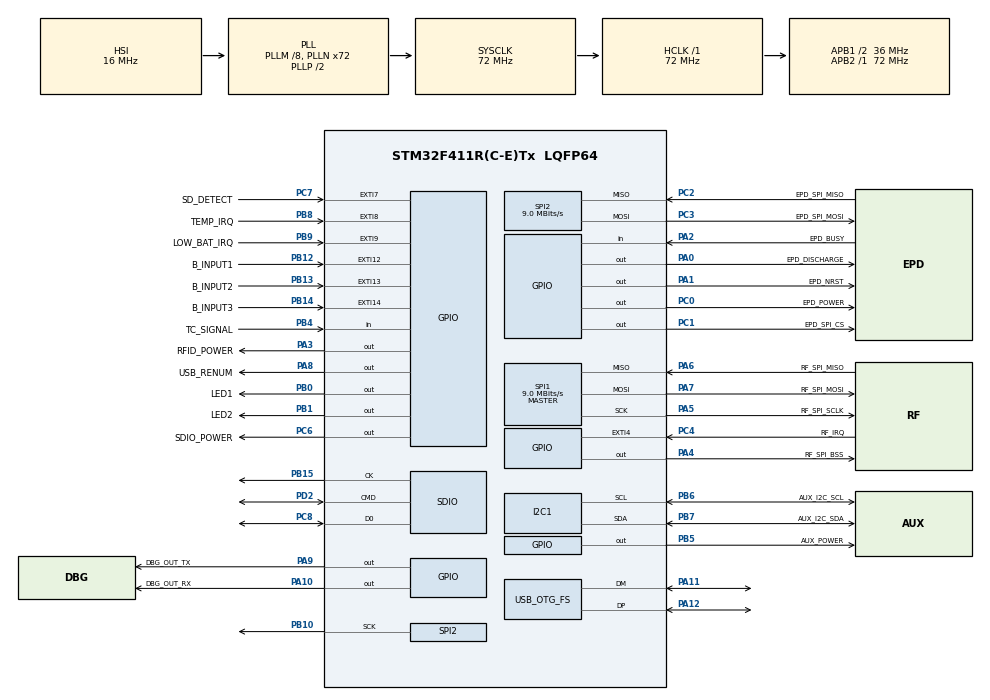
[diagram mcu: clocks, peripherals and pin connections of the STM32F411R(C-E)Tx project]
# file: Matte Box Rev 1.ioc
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FATFS._CODE_PAGE=437
FATFS._FS_RPATH=2
FATFS._MAX_SS=512
FATFS._USE_LFN=1
I2C1.I2C_Mode=I2C_Fast
Mcu.Family=STM32F4
Mcu.Name=STM32F411R(C-E)Tx
Mcu.Package=LQFP64
NVIC.EXTI15_10_IRQn=true\:0\:0\:false\:false\:true\:true\:true
NVIC.EXTI4_IRQn=true\:0\:0\:false\:false\:true\:true\:true
NVIC.EXTI9_5_IRQn=true\:0\:0\:false\:false\:true\:true\:true
NVIC.OTG_FS_IRQn=true\:0\:0\:true\:false\:true\:false\:true
NVIC.PriorityGroup=NVIC_PRIORITYGROUP_4
NVIC.SDIO_IRQn=true\:0\:0\:true\:false\:true\:true\:true
NVIC.SPI1_IRQn=true\:0\:0\:false\:false\:true\:true\:true
PA0-WKUP.GPIO_Label=EPD_DISCHARGE
PA0-WKUP.Signal=GPIO_Output
PA1.GPIO_Label=EPD_NRST
PA1.Signal=GPIO_Output
PA10.GPIO_Label=DBG_OUT_RX
PA10.Signal=GPIO_Output
PA11.Mode=Device_Only
PA11.Signal=USB_OTG_FS_DM
PA12.Mode=Device_Only
PA12.Signal=USB_OTG_FS_DP
PA13.Signal=SYS_JTMS-SWDIO
PA14.Signal=SYS_JTCK-SWCLK
PA15.Signal=SYS_JTDI
PA2.GPIO_Label=EPD_BUSY
PA2.Signal=GPIO_Input
PA3.GPIO_Label=RFID_POWER
PA3.Signal=GPIO_Output
PA4.GPIO_Label=RF_SPI_BSS
PA4.Signal=GPIO_Output
PA5.GPIO_Label=RF_SPI_SCLK
PA5.Mode=Full_Duplex_Master
PA5.Signal=SPI1_SCK
PA6.GPIO_Label=RF_SPI_MISO
PA6.Mode=Full_Duplex_Master
PA6.Signal=SPI1_MISO
PA7.GPIO_Label=RF_SPI_MOSI
PA7.Mode=Full_Duplex_Master
PA7.Signal=SPI1_MOSI
PA8.GPIO_Label=USB_RENUM
PA8.Signal=GPIO_Output
PA9.GPIO_Label=DBG_OUT_TX
PA9.Signal=GPIO_Output
PB0.GPIO_Label=LED1
PB0.Signal=GPIO_Output
PB1.GPIO_Label=LED2
PB1.Signal=GPIO_Output
PB10.Mode=Full_Duplex_Master
PB10.Signal=SPI2_SCK
PB12.GPIO_Label=B_INPUT1
PB12.GPIO_ModeDefaultEXTI=GPIO_MODE_IT_RISING_FALLING
PB12.GPIO_PuPd=GPIO_PULLDOWN
PB12.Signal=GPXTI12
PB13.GPIO_Label=B_INPUT2
PB13.GPIO_ModeDefaultEXTI=GPIO_MODE_IT_RISING_FALLING
PB13.GPIO_PuPd=GPIO_PULLDOWN
PB13.Signal=GPXTI13
PB14.GPIO_Label=B_INPUT3
PB14.GPIO_ModeDefaultEXTI=GPIO_MODE_IT_RISING_FALLING
PB14.GPIO_PuPd=GPIO_PULLDOWN
PB14.Signal=GPXTI14
PB15.Mode=SD_1_bit
PB15.Signal=SDIO_CK
PB3.Signal=SYS_JTDO-SWO
PB4.GPIO_Label=TC_SIGNAL
PB4.Signal=GPIO_Input
PB5.GPIO_Label=AUX_POWER
PB5.Signal=GPIO_Output
PB6.GPIO_Label=AUX_I2C_SCL
PB6.GPIO_PuPdOD=GPIO_PULLUP
PB6.Mode=I2C
PB6.Signal=I2C1_SCL
PB7.GPIO_Label=AUX_I2C_SDA
PB7.GPIO_PuPdOD=GPIO_PULLUP
PB7.Mode=I2C
PB7.Signal=I2C1_SDA
PB8.GPIO_Label=TEMP_IRQ
PB8.Signal=GPXTI8
PB9.GPIO_Label=LOW_BAT_IRQ
PB9.Signal=GPXTI9
PC0.GPIO_Label=EPD_POWER
PC0.Signal=GPIO_Output
PC1.GPIO_Label=EPD_SPI_CS
PC1.Signal=GPIO_Output
PC10.Signal=SDIO_D2
PC14-OSC32_IN.Mode=LSE-External-Oscillator
PC14-OSC32_IN.Signal=RCC_OSC32_IN
PC15-OSC32_OUT.Mode=LSE-External-Oscillator
PC15-OSC32_OUT.Signal=RCC_OSC32_OUT
PC2.GPIO_Label=EPD_SPI_MISO
PC2.Mode=Full_Duplex_Master
PC2.Signal=SPI2_MISO
PC3.GPIO_Label=EPD_SPI_MOSI
PC3.Mode=Full_Duplex_Master
PC3.Signal=SPI2_MOSI
PC4.GPIO_Label=RF_IRQ
PC4.Signal=GPXTI4
PC6.GPIO_Label=SDIO_POWER
PC6.Signal=GPIO_Output
PC7.GPIO_Label=SD_DETECT
PC7.GPIO_ModeDefaultEXTI=GPIO_MODE_IT_RISING_FALLING
PC7.GPIO_PuPd=GPIO_PULLUP
PC7.Signal=GPXTI7
PC8.Mode=SD_1_bit
PC8.Signal=SDIO_D0
PD2.Mode=SD_1_bit
PD2.Signal=SDIO_CMD
ProjectManager.HeapSize=0x400
ProjectManager.StackSize=0x800
ProjectManager.TargetToolchain=STM32CubeIDE
RCC.48MHZClocksFreq_Value=48000000
RCC.AHBFreq_Value=72000000
RCC.APB1CLKDivider=RCC_HCLK_DIV2
RCC.APB1Freq_Value=36000000
RCC.APB1TimFreq_Value=72000000
RCC.APB2Freq_Value=72000000
RCC.APB2TimCLKDivider=1
RCC.APB2TimFreq_Value=72000000
RCC.CortexFreq_Value=72000000
RCC.HCLKFreq_Value=72000000
RCC.HSE_VALUE=8000000
RCC.HSI_VALUE=16000000
RCC.PLLM=8
RCC.PLLN=72
RCC.PLLQ=3
RCC.PLLSource=RCC_PLLSOURCE_HSI
RCC.SYSCLKFreq_VALUE=72000000
RCC.SYSCLKSource=RCC_SYSCLKSOURCE_PLLCLK
RCC.VCOOutputFreq_Value=144000000
SDIO.ClockDiv=2
SPI1.BaudRatePrescaler=SPI_BAUDRATEPRESCALER_8
SPI1.CLKPhase=SPI_PHASE_2EDGE
SPI1.CalculateBaudRate=9.0 MBits/s
SPI1.Direction=SPI_DIRECTION_2LINES
SPI1.Mode=SPI_MODE_MASTER
SPI1.VirtualType=VM_MASTER
SPI2.BaudRatePrescaler=SPI_BAUDRATEPRESCALER_4
SPI2.CalculateBaudRate=9.0 MBits/s
SPI2.Direction=SPI_DIRECTION_2LINES
SPI2.Mode=SPI_MODE_MASTER
SPI2.VirtualType=VM_MASTER
USB_DEVICE.CLASS_NAME_FS=CDC
USB_DEVICE.USBD_SELF_POWERED=1
USB_DEVICE.VirtualMode=Cdc
USB_DEVICE.VirtualModeFS=Cdc_FS
USB_OTG_FS.VirtualMode=Device_Only
VP_FATFS_VS_SDIO.Mode=SDIO
VP_RTC_VS_RTC_Activate.Mode=RTC_Enabled
VP_RTC_VS_RTC_Calendar.Mode=RTC_Calendar
VP_USB_DEVICE_VS_USB_DEVICE_CDC_FS.Mode=CDC_FS
board=custom

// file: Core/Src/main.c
/* USER CODE BEGIN Header */
/**
  ******************************************************************************
  * @file           : main.c
  * @brief          : Main program body
  ******************************************************************************
  * @attention
  *
  * <h2><center>&copy; Copyright (c) 2020 STMicroelectronics.
  * All rights reserved.</center></h2>
  *
  * This software component is licensed by ST under BSD 3-Clause license,
  * the "License"; You may not use this file except in compliance with the
  * License. You may obtain a copy of the License at:
  *                        opensource.org/licenses/BSD-3-Clause
  *
  ******************************************************************************
  */
/* USER CODE END Header */

#include "main.h"
#include "fatfs.h"
#include "usb_device.h"

/* USER CODE BEGIN Includes */
#include "process_controller.h"
/* USER CODE END Includes */

I2C_HandleTypeDef hi2c1;

RTC_HandleTypeDef hrtc;

SD_HandleTypeDef hsd;

SPI_HandleTypeDef hspi1;
SPI_HandleTypeDef hspi2;

void SystemClock_Config(void);
static void MX_GPIO_Init(void);
static void MX_I2C1_Init(void);
static void MX_SDIO_SD_Init(void);
static void MX_SPI1_Init(void);
static void MX_SPI2_Init(void);
static void MX_RTC_Init(void);

int main(void)
{

  /* MCU Configuration--------------------------------------------------------*/

  /* Reset of all peripherals, Initializes the Flash interface and the Systick. */
  HAL_Init();

  /* Configure the system clock */
  SystemClock_Config();

  /* Initialize all configured peripherals */
  MX_GPIO_Init();
  MX_I2C1_Init();
  MX_SDIO_SD_Init();
  MX_SPI1_Init();
  MX_SPI2_Init();
//  MX_FATFS_Init();
  MX_USB_DEVICE_Init();
  MX_RTC_Init();
  /* USER CODE BEGIN 2 */
  setupIOs();						/* Main Setup 			*/
  /* USER CODE END 2 */

  /* Infinite loop */
  while (1)
  {

    /* USER CODE BEGIN 3 */
	  processIOs();					/* Main Process 		*/
  }
  /* USER CODE END 3 */
}

void SystemClock_Config(void)
{
  RCC_OscInitTypeDef RCC_OscInitStruct = {0};
  RCC_ClkInitTypeDef RCC_ClkInitStruct = {0};
  RCC_PeriphCLKInitTypeDef PeriphClkInitStruct = {0};

  /** Configure the main internal regulator output voltage
  */
  __HAL_RCC_PWR_CLK_ENABLE();
  __HAL_PWR_VOLTAGESCALING_CONFIG(PWR_REGULATOR_VOLTAGE_SCALE1);
  /** Initializes the CPU, AHB and APB busses clocks
  */
  RCC_OscInitStruct.OscillatorType = RCC_OSCILLATORTYPE_HSI|RCC_OSCILLATORTYPE_LSI;
  RCC_OscInitStruct.HSIState = RCC_HSI_ON;
  RCC_OscInitStruct.HSICalibrationValue = RCC_HSICALIBRATION_DEFAULT;
  RCC_OscInitStruct.LSIState = RCC_LSI_ON;
  RCC_OscInitStruct.PLL.PLLState = RCC_PLL_ON;
  RCC_OscInitStruct.PLL.PLLSource = RCC_PLLSOURCE_HSI;
  RCC_OscInitStruct.PLL.PLLM = 8;
  RCC_OscInitStruct.PLL.PLLN = 72;
  RCC_OscInitStruct.PLL.PLLP = RCC_PLLP_DIV2;
  RCC_OscInitStruct.PLL.PLLQ = 3;
  if (HAL_RCC_OscConfig(&RCC_OscInitStruct) != HAL_OK)
  {
    Error_Handler();
  }
  /** Initializes the CPU, AHB and APB busses clocks
  */
  RCC_ClkInitStruct.ClockType = RCC_CLOCKTYPE_HCLK|RCC_CLOCKTYPE_SYSCLK
                              |RCC_CLOCKTYPE_PCLK1|RCC_CLOCKTYPE_PCLK2;
  RCC_ClkInitStruct.SYSCLKSource = RCC_SYSCLKSOURCE_PLLCLK;
  RCC_ClkInitStruct.AHBCLKDivider = RCC_SYSCLK_DIV1;
  RCC_ClkInitStruct.APB1CLKDivider = RCC_HCLK_DIV2;
  RCC_ClkInitStruct.APB2CLKDivider = RCC_HCLK_DIV1;

  if (HAL_RCC_ClockConfig(&RCC_ClkInitStruct, FLASH_LATENCY_2) != HAL_OK)
  {
    Error_Handler();
  }
  PeriphClkInitStruct.PeriphClockSelection = RCC_PERIPHCLK_RTC;
  PeriphClkInitStruct.RTCClockSelection = RCC_RTCCLKSOURCE_LSI;
  if (HAL_RCCEx_PeriphCLKConfig(&PeriphClkInitStruct) != HAL_OK)
  {
    Error_Handler();
  }
}

static void MX_I2C1_Init(void)
{

  hi2c1.Instance = I2C1;
  hi2c1.Init.ClockSpeed = 400000;
  hi2c1.Init.DutyCycle = I2C_DUTYCYCLE_2;
  hi2c1.Init.OwnAddress1 = 0;
  hi2c1.Init.AddressingMode = I2C_ADDRESSINGMODE_7BIT;
  hi2c1.Init.DualAddressMode = I2C_DUALADDRESS_DISABLE;
  hi2c1.Init.OwnAddress2 = 0;
  hi2c1.Init.GeneralCallMode = I2C_GENERALCALL_DISABLE;
  hi2c1.Init.NoStretchMode = I2C_NOSTRETCH_DISABLE;
  if (HAL_I2C_Init(&hi2c1) != HAL_OK)
  {
    Error_Handler();
  }

}

static void MX_RTC_Init(void)
{

  RTC_TimeTypeDef sTime = {0};
  RTC_DateTypeDef sDate = {0};

  /** Initialize RTC Only
  */
  hrtc.Instance = RTC;
  hrtc.Init.HourFormat = RTC_HOURFORMAT_24;
  hrtc.Init.AsynchPrediv = 127;
  hrtc.Init.SynchPrediv = 255;
  hrtc.Init.OutPut = RTC_OUTPUT_DISABLE;
  hrtc.Init.OutPutPolarity = RTC_OUTPUT_POLARITY_HIGH;
  hrtc.Init.OutPutType = RTC_OUTPUT_TYPE_OPENDRAIN;
  if (HAL_RTC_Init(&hrtc) != HAL_OK)
  {
    Error_Handler();
  }

  /** Initialize RTC and set the Time and Date
  */
  sTime.Hours = 0x0;
  sTime.Minutes = 0x0;
  sTime.Seconds = 0x0;
  sTime.DayLightSaving = RTC_DAYLIGHTSAVING_NONE;
  sTime.StoreOperation = RTC_STOREOPERATION_RESET;
  if (HAL_RTC_SetTime(&hrtc, &sTime, RTC_FORMAT_BCD) != HAL_OK)
  {
    Error_Handler();
  }
  sDate.WeekDay = RTC_WEEKDAY_MONDAY;
  sDate.Month = RTC_MONTH_JANUARY;
  sDate.Date = 0x1;
  sDate.Year = 0x0;

  if (HAL_RTC_SetDate(&hrtc, &sDate, RTC_FORMAT_BCD) != HAL_OK)
  {
    Error_Handler();
  }

}

static void MX_SDIO_SD_Init(void)
{

  hsd.Instance = SDIO;
  hsd.Init.ClockEdge = SDIO_CLOCK_EDGE_RISING;
  hsd.Init.ClockBypass = SDIO_CLOCK_BYPASS_DISABLE;
  hsd.Init.ClockPowerSave = SDIO_CLOCK_POWER_SAVE_DISABLE;
  hsd.Init.BusWide = SDIO_BUS_WIDE_1B;
  hsd.Init.HardwareFlowControl = SDIO_HARDWARE_FLOW_CONTROL_DISABLE;
  hsd.Init.ClockDiv = 2;

}

static void MX_SPI1_Init(void)
{

  /* SPI1 parameter configuration*/
  hspi1.Instance = SPI1;
  hspi1.Init.Mode = SPI_MODE_MASTER;
  hspi1.Init.Direction = SPI_DIRECTION_2LINES;
  hspi1.Init.DataSize = SPI_DATASIZE_8BIT;
  hspi1.Init.CLKPolarity = SPI_POLARITY_LOW;
  hspi1.Init.CLKPhase = SPI_PHASE_2EDGE;
  hspi1.Init.NSS = SPI_NSS_SOFT;
  hspi1.Init.BaudRatePrescaler = SPI_BAUDRATEPRESCALER_8;
  hspi1.Init.FirstBit = SPI_FIRSTBIT_MSB;
  hspi1.Init.TIMode = SPI_TIMODE_DISABLE;
  hspi1.Init.CRCCalculation = SPI_CRCCALCULATION_DISABLE;
  hspi1.Init.CRCPolynomial = 10;
  if (HAL_SPI_Init(&hspi1) != HAL_OK)
  {
    Error_Handler();
  }

}

static void MX_SPI2_Init(void)
{

  /* SPI2 parameter configuration*/
  hspi2.Instance = SPI2;
  hspi2.Init.Mode = SPI_MODE_MASTER;
  hspi2.Init.Direction = SPI_DIRECTION_2LINES;
  hspi2.Init.DataSize = SPI_DATASIZE_8BIT;
  hspi2.Init.CLKPolarity = SPI_POLARITY_LOW;
  hspi2.Init.CLKPhase = SPI_PHASE_1EDGE;
  hspi2.Init.NSS = SPI_NSS_SOFT;
  hspi2.Init.BaudRatePrescaler = SPI_BAUDRATEPRESCALER_4;
  hspi2.Init.FirstBit = SPI_FIRSTBIT_MSB;
  hspi2.Init.TIMode = SPI_TIMODE_DISABLE;
  hspi2.Init.CRCCalculation = SPI_CRCCALCULATION_DISABLE;
  hspi2.Init.CRCPolynomial = 10;
  if (HAL_SPI_Init(&hspi2) != HAL_OK)
  {
    Error_Handler();
  }

}

static void MX_GPIO_Init(void)
{
  GPIO_InitTypeDef GPIO_InitStruct = {0};

  /* GPIO Ports Clock Enable */
  __HAL_RCC_GPIOC_CLK_ENABLE();
  __HAL_RCC_GPIOA_CLK_ENABLE();
  __HAL_RCC_GPIOB_CLK_ENABLE();
  __HAL_RCC_GPIOD_CLK_ENABLE();

  /*Configure GPIO pin Output Level */
  HAL_GPIO_WritePin(GPIOC, EPD_POWER_Pin|EPD_SPI_CS_Pin|SDIO_POWER_Pin, GPIO_PIN_RESET);

  /*Configure GPIO pin Output Level */
  HAL_GPIO_WritePin(GPIOA, EPD_DISCHARGE_Pin|EPD_NRST_Pin|RFID_POWER_Pin|RF_SPI_BSS_Pin
                          |USB_RENUM_Pin|DBG_OUT_TX_Pin|DBG_OUT_RX_Pin, GPIO_PIN_RESET);

  /*Configure GPIO pin Output Level */
  HAL_GPIO_WritePin(GPIOB, LED1_Pin|LED2_Pin|AUX_POWER_Pin, GPIO_PIN_RESET);

  /*Configure GPIO pins : EPD_POWER_Pin EPD_SPI_CS_Pin SDIO_POWER_Pin */
  GPIO_InitStruct.Pin = EPD_POWER_Pin|EPD_SPI_CS_Pin|SDIO_POWER_Pin;
  GPIO_InitStruct.Mode = GPIO_MODE_OUTPUT_PP;
  GPIO_InitStruct.Pull = GPIO_NOPULL;
  GPIO_InitStruct.Speed = GPIO_SPEED_FREQ_LOW;
  HAL_GPIO_Init(GPIOC, &GPIO_InitStruct);

  /*Configure GPIO pins : EPD_DISCHARGE_Pin EPD_NRST_Pin RFID_POWER_Pin RF_SPI_BSS_Pin
                           USB_RENUM_Pin DBG_OUT_TX_Pin DBG_OUT_RX_Pin */
  GPIO_InitStruct.Pin = EPD_DISCHARGE_Pin|EPD_NRST_Pin|RFID_POWER_Pin|RF_SPI_BSS_Pin
                          |USB_RENUM_Pin|DBG_OUT_TX_Pin|DBG_OUT_RX_Pin;
  GPIO_InitStruct.Mode = GPIO_MODE_OUTPUT_PP;
  GPIO_InitStruct.Pull = GPIO_NOPULL;
  GPIO_InitStruct.Speed = GPIO_SPEED_FREQ_LOW;
  HAL_GPIO_Init(GPIOA, &GPIO_InitStruct);

  /*Configure GPIO pin : EPD_BUSY_Pin */
  GPIO_InitStruct.Pin = EPD_BUSY_Pin;
  GPIO_InitStruct.Mode = GPIO_MODE_INPUT;
  GPIO_InitStruct.Pull = GPIO_NOPULL;
  HAL_GPIO_Init(EPD_BUSY_GPIO_Port, &GPIO_InitStruct);

  /*Configure GPIO pin : RF_IRQ_Pin */
  GPIO_InitStruct.Pin = RF_IRQ_Pin;
  GPIO_InitStruct.Mode = GPIO_MODE_IT_RISING;
  GPIO_InitStruct.Pull = GPIO_NOPULL;
  HAL_GPIO_Init(RF_IRQ_GPIO_Port, &GPIO_InitStruct);

  /*Configure GPIO pins : LED1_Pin LED2_Pin AUX_POWER_Pin */
  GPIO_InitStruct.Pin = LED1_Pin|LED2_Pin|AUX_POWER_Pin;
  GPIO_InitStruct.Mode = GPIO_MODE_OUTPUT_PP;
  GPIO_InitStruct.Pull = GPIO_NOPULL;
  GPIO_InitStruct.Speed = GPIO_SPEED_FREQ_LOW;
  HAL_GPIO_Init(GPIOB, &GPIO_InitStruct);

  /*Configure GPIO pins : B_INPUT1_Pin B_INPUT2_Pin B_INPUT3_Pin */
  GPIO_InitStruct.Pin = B_INPUT1_Pin|B_INPUT2_Pin|B_INPUT3_Pin;
  GPIO_InitStruct.Mode = GPIO_MODE_IT_RISING_FALLING;
  GPIO_InitStruct.Pull = GPIO_PULLDOWN;
  HAL_GPIO_Init(GPIOB, &GPIO_InitStruct);

  /*Configure GPIO pin : SD_DETECT_Pin */
  GPIO_InitStruct.Pin = SD_DETECT_Pin;
  GPIO_InitStruct.Mode = GPIO_MODE_IT_RISING_FALLING;
  GPIO_InitStruct.Pull = GPIO_PULLUP;
  HAL_GPIO_Init(SD_DETECT_GPIO_Port, &GPIO_InitStruct);

  /*Configure GPIO pin : TC_SIGNAL_Pin */
  GPIO_InitStruct.Pin = TC_SIGNAL_Pin;
  GPIO_InitStruct.Mode = GPIO_MODE_INPUT;
  GPIO_InitStruct.Pull = GPIO_NOPULL;
  HAL_GPIO_Init(TC_SIGNAL_GPIO_Port, &GPIO_InitStruct);

  /*Configure GPIO pins : TEMP_IRQ_Pin LOW_BAT_IRQ_Pin */
  GPIO_InitStruct.Pin = TEMP_IRQ_Pin|LOW_BAT_IRQ_Pin;
  GPIO_InitStruct.Mode = GPIO_MODE_IT_RISING;
  GPIO_InitStruct.Pull = GPIO_NOPULL;
  HAL_GPIO_Init(GPIOB, &GPIO_InitStruct);

  /* EXTI interrupt init*/
  HAL_NVIC_SetPriority(EXTI4_IRQn, 0, 0);
  HAL_NVIC_EnableIRQ(EXTI4_IRQn);

  HAL_NVIC_SetPriority(EXTI9_5_IRQn, 0, 0);
  HAL_NVIC_EnableIRQ(EXTI9_5_IRQn);

  HAL_NVIC_SetPriority(EXTI15_10_IRQn, 0, 0);
  HAL_NVIC_EnableIRQ(EXTI15_10_IRQn);

}

void Error_Handler(void)
{
}

/************************ (C) COPYRIGHT STMicroelectronics *****END OF FILE****/
